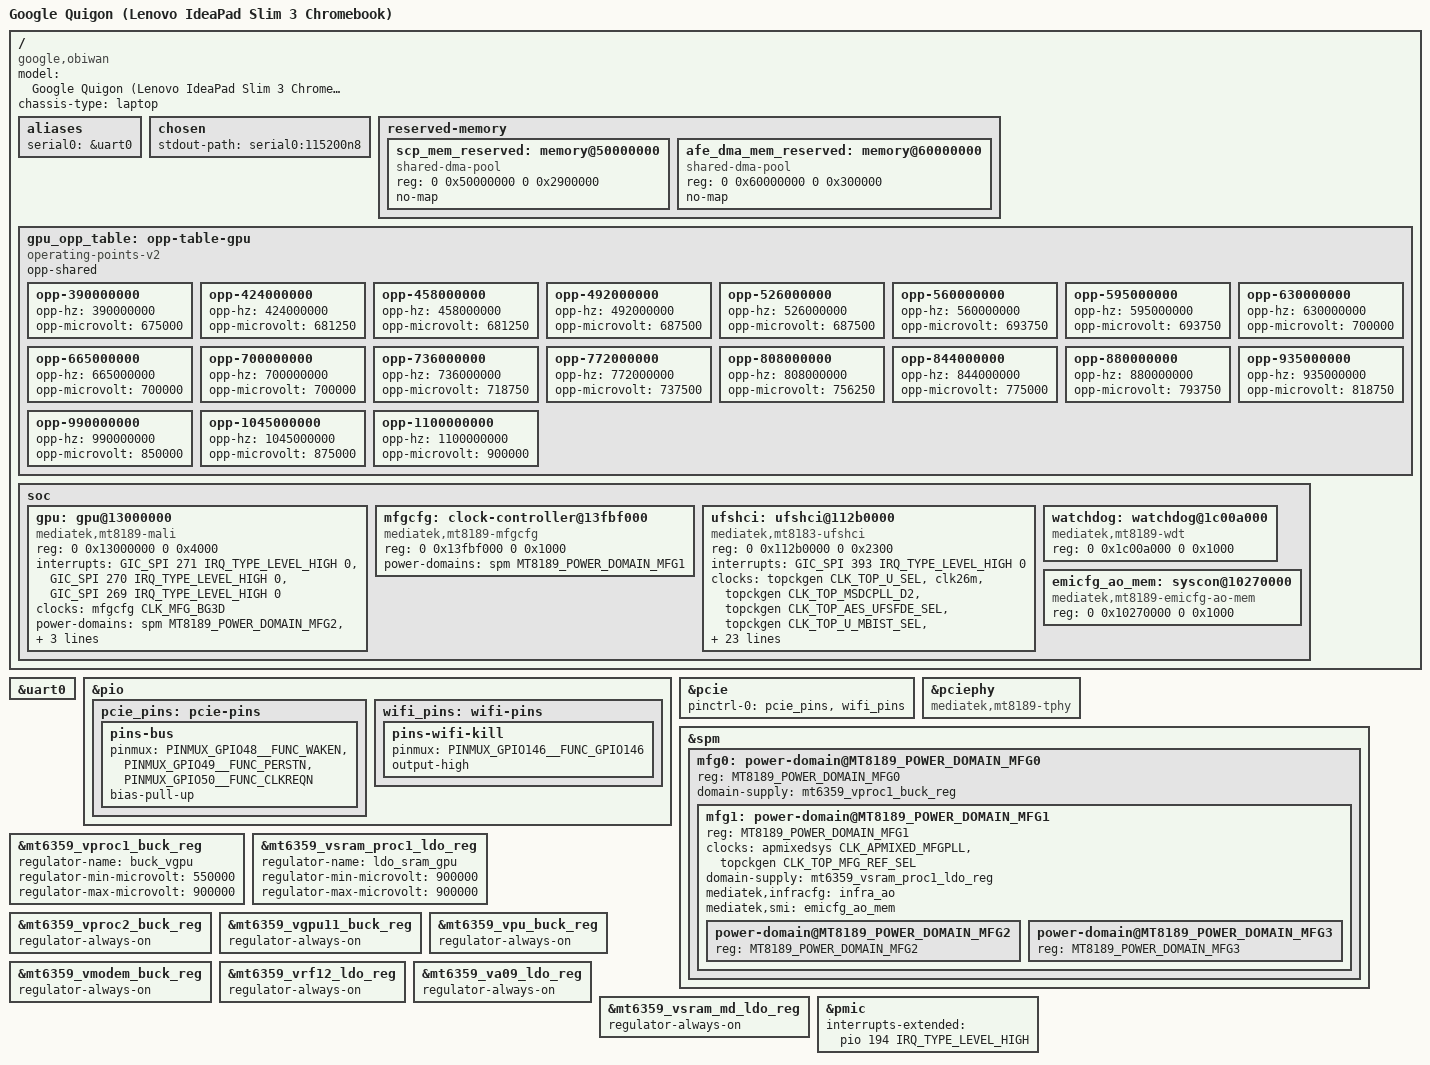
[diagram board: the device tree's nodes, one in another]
// SPDX-License-Identifier: (GPL-2.0 OR MIT)
/*
 * Mainline bring-up device tree for the Lenovo IdeaPad Slim 3 Chromebook (14M8911), ChromeOS board "quigon" on the
 * "obiwan" baseboard (MT8189 / Kompanio 540). Builds on mt8189.dtsi from Collabora's Genio 520/720-EVK series.
 *
 * mt8189-pinfunc.h is ChromeOS's (the mainline pinmux header patch isn't merged yet).
 *
 * Storage: UFS (from ChromeOS), so test kernels can use Omarchy's root read-only.
 * Stage 3 (GPU): MFG clock + power domains + Panfrost node (ChromeOS's full OPP table, SRAM rail fixed at 900 mV).
 *
 * Stage 1: CPUs, GIC, timer, clocks, pinctrl, power domains, watchdog, PCIe + MT7921 Wi-Fi, MT6359 PMIC (on the pwrap; MT6319 on SPMI for
 * the big cores isn't described yet, firmware sets it up). No UART is reachable without a SuzyQ cable,
 * so the console goes to ramoops (pstore), which the firmware describes in /reserved-memory on every boot. The
 * firmware also fills in /memory (without the BL31 region) and adds /firmware/coreboot.
 */
/dts-v1/;
#include "mt8189.dtsi"
#include "mt6359.dtsi"
#include "mt8189-pinfunc.h"
#include <dt-bindings/clock/mediatek,mt8189-clk.h>
#include <dt-bindings/reset/mediatek,mt8189-resets.h>

/ {
	model = "Google Quigon (Lenovo IdeaPad Slim 3 Chromebook)";
	chassis-type = "laptop";
	compatible = "google,obiwan", "mediatek,mt8189";

	aliases {
		serial0 = &uart0;
	};

	chosen {
		stdout-path = "serial0:115200n8";
	};

	reserved-memory {
		#address-cells = <2>;
		#size-cells = <2>;
		ranges;

		/* Same as ChromeOS: SCP firmware memory and the audio DMA pool. */
		scp_mem_reserved: memory@50000000 {
			compatible = "shared-dma-pool";
			reg = <0 0x50000000 0 0x2900000>;
			no-map;
		};

		afe_dma_mem_reserved: memory@60000000 {
			compatible = "shared-dma-pool";
			reg = <0 0x60000000 0 0x300000>;
			no-map;
		};
	};

	/* ChromeOS's GPU OPP table (390-1100 MHz); vsram_proc1 is fixed at 900 mV (see below). */
	gpu_opp_table: opp-table-gpu {
		compatible = "operating-points-v2";
		opp-shared;

		opp-390000000 {
			opp-hz = /bits/ 64 <390000000>;
			opp-microvolt = <675000>;
		};
		opp-424000000 {
			opp-hz = /bits/ 64 <424000000>;
			opp-microvolt = <681250>;
		};
		opp-458000000 {
			opp-hz = /bits/ 64 <458000000>;
			opp-microvolt = <681250>;
		};
		opp-492000000 {
			opp-hz = /bits/ 64 <492000000>;
			opp-microvolt = <687500>;
		};
		opp-526000000 {
			opp-hz = /bits/ 64 <526000000>;
			opp-microvolt = <687500>;
		};
		opp-560000000 {
			opp-hz = /bits/ 64 <560000000>;
			opp-microvolt = <693750>;
		};
		opp-595000000 {
			opp-hz = /bits/ 64 <595000000>;
			opp-microvolt = <693750>;
		};
		opp-630000000 {
			opp-hz = /bits/ 64 <630000000>;
			opp-microvolt = <700000>;
		};
		opp-665000000 {
			opp-hz = /bits/ 64 <665000000>;
			opp-microvolt = <700000>;
		};
		opp-700000000 {
			opp-hz = /bits/ 64 <700000000>;
			opp-microvolt = <700000>;
		};
		opp-736000000 {
			opp-hz = /bits/ 64 <736000000>;
			opp-microvolt = <718750>;
		};
		opp-772000000 {
			opp-hz = /bits/ 64 <772000000>;
			opp-microvolt = <737500>;
		};
		opp-808000000 {
			opp-hz = /bits/ 64 <808000000>;
			opp-microvolt = <756250>;
		};
		opp-844000000 {
			opp-hz = /bits/ 64 <844000000>;
			opp-microvolt = <775000>;
		};
		opp-880000000 {
			opp-hz = /bits/ 64 <880000000>;
			opp-microvolt = <793750>;
		};
		opp-935000000 {
			opp-hz = /bits/ 64 <935000000>;
			opp-microvolt = <818750>;
		};
		opp-990000000 {
			opp-hz = /bits/ 64 <990000000>;
			opp-microvolt = <850000>;
		};
		opp-1045000000 {
			opp-hz = /bits/ 64 <1045000000>;
			opp-microvolt = <875000>;
		};
		opp-1100000000 {
			opp-hz = /bits/ 64 <1100000000>;
			opp-microvolt = <900000>;
		};
	};

	soc {
		/* Mali-G57 MC2 (Valhall JM), from ChromeOS; Panfrost treats it like the MT8370's (2 power domains). */
		gpu: gpu@13000000 {
			compatible = "mediatek,mt8189-mali", "arm,mali-valhall-jm";
			reg = <0 0x13000000 0 0x4000>;
			interrupts = <GIC_SPI 271 IRQ_TYPE_LEVEL_HIGH 0>,
				     <GIC_SPI 270 IRQ_TYPE_LEVEL_HIGH 0>,
				     <GIC_SPI 269 IRQ_TYPE_LEVEL_HIGH 0>;
			interrupt-names = "job", "mmu", "gpu";
			clocks = <&mfgcfg CLK_MFG_BG3D>;
			power-domains = <&spm MT8189_POWER_DOMAIN_MFG2>,
					<&spm MT8189_POWER_DOMAIN_MFG3>;
			power-domain-names = "core0", "core1";
			operating-points-v2 = <&gpu_opp_table>;
			mali-supply = <&mt6359_vproc1_buck_reg>;
			#cooling-cells = <2>;
		};

		/*
		 * GPU clock gates. The registers sit inside the MFG power domain: reading the gate state with it off is a
		 * bus error (SError panic seen when reading clk_summary), so tie the controller to the domain (the driver
		 * uses runtime PM).
		 */
		mfgcfg: clock-controller@13fbf000 {
			compatible = "mediatek,mt8189-mfgcfg";
			reg = <0 0x13fbf000 0 0x1000>;
			power-domains = <&spm MT8189_POWER_DOMAIN_MFG1>;
			#clock-cells = <1>;
		};

		/*
		 * Internal storage: UFS host, from ChromeOS (the generic mt8183 binding mainline's ufs-mediatek handles). The
		 * clocks and resets come from the Genio series' ufscfg-ao/-pdn controllers (unlabelled there: path refs).
		 */
		ufshci: ufshci@112b0000 {
			compatible = "mediatek,mt8183-ufshci";
			reg = <0 0x112b0000 0 0x2300>;
			interrupts = <GIC_SPI 393 IRQ_TYPE_LEVEL_HIGH 0>;
			clocks = <&topckgen CLK_TOP_U_SEL>,
				 <&clk26m>,
				 <&topckgen CLK_TOP_MSDCPLL_D2>,
				 <&topckgen CLK_TOP_AES_UFSFDE_SEL>,
				 <&topckgen CLK_TOP_U_MBIST_SEL>,
				 <&{/soc/clock-controller@112b8000} CLK_UFSCFG_AO_REG_UNIPRO_TX_SYM>,
				 <&{/soc/clock-controller@112b8000} CLK_UFSCFG_AO_REG_UNIPRO_RX_SYM0>,
				 <&{/soc/clock-controller@112b8000} CLK_UFSCFG_AO_REG_UNIPRO_RX_SYM1>,
				 <&{/soc/clock-controller@112b8000} CLK_UFSCFG_AO_REG_UNIPRO_SYS>,
				 <&{/soc/clock-controller@112b8000} CLK_UFSCFG_AO_REG_U_SAP_CFG>,
				 <&{/soc/clock-controller@112b8000} CLK_UFSCFG_AO_REG_U_PHY_TOP_AHB_S_BUS>,
				 <&{/soc/clock-controller@112bb000} CLK_UFSCFG_REG_UFSHCI_UFS>,
				 <&{/soc/clock-controller@112bb000} CLK_UFSCFG_REG_UFSHCI_AES>,
				 <&{/soc/clock-controller@112bb000} CLK_UFSCFG_REG_UFSHCI_U_AHB>,
				 <&{/soc/clock-controller@112bb000} CLK_UFSCFG_REG_UFSHCI_U_AXI>;
			clock-names = "ufs_sel", "ufs_sel_min_src", "ufs_sel_max_src", "ufs_fde", "ufs_mbist",
				      "unipro_tx_sym", "unipro_rx_sym0", "unipro_rx_sym1", "unipro_sys", "unipro_phy_sap",
				      "phy_top_ahb_s_bus", "ufshci_ufs", "ufshci_aes", "ufshci_ufs_ahb", "ufshci_aes_axi";
			freq-table-hz = <26000000 208000000>, <0 0>, <0 0>, <0 0>, <0 0>, <0 0>, <0 0>, <0 0>,
					<0 0>, <0 0>, <0 0>, <0 0>, <0 0>, <0 0>, <0 0>;
			vcc-supply = <&mt6359_vemc_1_ldo_reg>;
			vccq-supply = <&mt6359_vio18_ldo_reg>;
			vccq2-supply = <&mt6359_vufs_ldo_reg>;
			resets = <&{/soc/clock-controller@112bb000} MT8189_UFSPDN_RST_UFS_UNIPRO>,
				 <&{/soc/clock-controller@112bb000} MT8189_UFSPDN_RST_UFS_CRYPTO>,
				 <&{/soc/clock-controller@112bb000} MT8189_UFSPDN_RST_UFS_HCI>,
				 <&{/soc/clock-controller@112b8000} MT8189_UFSAO_RST_UFS_MPHY>;
			reset-names = "unipro_rst", "crypto_rst", "hci_rst", "mphy_rst";
			mediatek,ufs-disable-mcq;
			/* not mediatek,ufs-rtff-mtcmos: switching the UFS power island off in system suspend (as ChromeOS does)
			 * left the host unusable after resume here (commands failing, then an SError) */
			mediatek,ufs-broken-vcc;
		};

		watchdog: watchdog@1c00a000 {
			compatible = "mediatek,mt8189-wdt", "mediatek,mt6589-wdt";
			reg = <0 0x1c00a000 0 0x1000>;
			#reset-cells = <1>;
		};
	};
};

&uart0 {
	status = "okay";
};

&pio {
	/* ChromeOS skywalker */
	pcie_pins: pcie-pins {
		pins-bus {
			pinmux = <PINMUX_GPIO48__FUNC_WAKEN>,
				 <PINMUX_GPIO49__FUNC_PERSTN>,
				 <PINMUX_GPIO50__FUNC_CLKREQN>;
			bias-pull-up;
		};
	};

	wifi_pins: wifi-pins {
		pins-wifi-kill {
			pinmux = <PINMUX_GPIO146__FUNC_GPIO146>;
			output-high;
		};
	};
};

/* MT7921 (MT7961) Wi-Fi on PCIe */
&pcie {
	pinctrl-names = "default";
	pinctrl-0 = <&pcie_pins>, <&wifi_pins>;
	status = "okay";
};

&pciephy {
	/*
	 * ChromeOS (MediaTek's tree, which works on this board) uses the v2 T-PHY register layout for MT8189; the
	 * Genio series' mt8189.dtsi says v3. With v3 the PCIe bring-up froze the SoC hard (no watchdog reset).
	 */
	compatible = "mediatek,mt8189-tphy", "mediatek,generic-tphy-v2";
	status = "okay";
};

/*
 * MFG1's bus protection has a step in the EMI config (GALS sleep protect, set/clear at 0x84/0x88), which the
 * power-controller driver finds through a "mediatek,smi" phandle (its legacy regmap lookup; the access-controllers
 * property would make fw_devlink wait for a driver this syscon never gets). Without it the lookup fell back to index
 * 0 and the step wrote into INFRACFG_AO instead; MFG1 only cycles in system suspend, after which the display faulted
 * (SError) as soon as it fetched pixels again. The EMI config block is ChromeOS's scpsys "emicfg-ao-mem".
 */
/ {
	soc {
		emicfg_ao_mem: syscon@10270000 {
			compatible = "mediatek,mt8189-emicfg-ao-mem", "syscon";
			reg = <0 0x10270000 0 0x1000>;
		};
	};
};

/* GPU power domains (not in the Genio series' mt8189.dtsi): MFG0 > MFG1 > MFG2, MFG3, like MT8188, with ChromeOS's
 * supplies (mfg0: vproc1 = GPU core rail, mfg1: vsram_proc1 = GPU SRAM rail) and MFG clocks. */
&spm {
	mfg0: power-domain@MT8189_POWER_DOMAIN_MFG0 {
		reg = <MT8189_POWER_DOMAIN_MFG0>;
		domain-supply = <&mt6359_vproc1_buck_reg>;
		#address-cells = <1>;
		#size-cells = <0>;
		#power-domain-cells = <1>;

		mfg1: power-domain@MT8189_POWER_DOMAIN_MFG1 {
			reg = <MT8189_POWER_DOMAIN_MFG1>;
			clocks = <&apmixedsys CLK_APMIXED_MFGPLL>,
				 <&topckgen CLK_TOP_MFG_REF_SEL>;
			clock-names = "mfg", "alt";
			domain-supply = <&mt6359_vsram_proc1_ldo_reg>;
			mediatek,infracfg = <&infra_ao>;
			mediatek,smi = <&emicfg_ao_mem>;
			#address-cells = <1>;
			#size-cells = <0>;
			#power-domain-cells = <1>;

			power-domain@MT8189_POWER_DOMAIN_MFG2 {
				reg = <MT8189_POWER_DOMAIN_MFG2>;
				#power-domain-cells = <0>;
			};

			power-domain@MT8189_POWER_DOMAIN_MFG3 {
				reg = <MT8189_POWER_DOMAIN_MFG3>;
				#power-domain-cells = <0>;
			};
		};
	};
};

/*
 * ChromeOS skywalker: GPU core and SRAM rails. ChromeOS couples them. In mainline, mtk-regulator-coupler only
 * attaches to names containing "vgpu"/"sram" (the stock "vproc1" fails -ENOTSUPP and takes the whole MT6359 regulator
 * probe down), and when it does attach, powering MFG1 fails -EPERM (s3e). So: no coupling, SRAM fixed at its 900 mV
 * maximum, which keeps it >= the core rail at every OPP (the only thing the coupling guarantees).
 */
&mt6359_vproc1_buck_reg {
	regulator-name = "buck_vgpu";
	regulator-min-microvolt = <550000>;
	regulator-max-microvolt = <900000>;
};

&mt6359_vsram_proc1_ldo_reg {
	regulator-name = "ldo_sram_gpu";
	regulator-min-microvolt = <900000>;
	regulator-max-microvolt = <900000>;
};

/*
 * Rails the bootloader leaves on that no Linux driver here claims: vproc2 (CPU DVFS is firmware-controlled, so cpufreq
 * holds no regulator), vgpu11, vpu, vmodem, vrf12, va09, vsram_md. Kept on explicitly so the kernel can disable unused
 * regulators (no regulator_ignore_unused); which of them are really needed on MT8189 is untested.
 */
&mt6359_vproc2_buck_reg { regulator-always-on; };
&mt6359_vgpu11_buck_reg { regulator-always-on; };
&mt6359_vpu_buck_reg { regulator-always-on; };
&mt6359_vmodem_buck_reg { regulator-always-on; };
&mt6359_vrf12_ldo_reg { regulator-always-on; };
&mt6359_va09_ldo_reg { regulator-always-on; };
&mt6359_vsram_md_ldo_reg { regulator-always-on; };

&pmic {
	/* ChromeOS skywalker: PMIC interrupt on GPIO 194 */
	interrupts-extended = <&pio 194 IRQ_TYPE_LEVEL_HIGH>;
};

